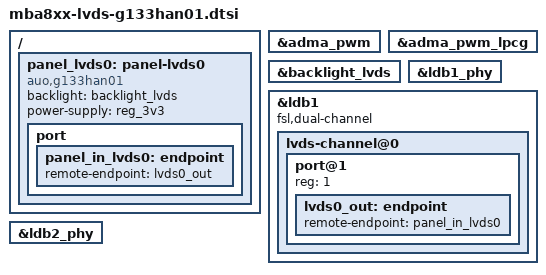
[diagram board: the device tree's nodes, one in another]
// SPDX-License-Identifier: (GPL-2.0-or-later OR MIT)
/*
 * Copyright (c) 2021-2023 TQ-Systems GmbH <linux@ew.tq-group.com>,
 * D-82229 Seefeld, Germany.
 * Author: Alexander Stein
 */

/ {
	panel_lvds0: panel-lvds0 {
		compatible = "auo,g133han01";
		backlight = <&backlight_lvds>;
		power-supply = <&reg_3v3>;

		port {
			panel_in_lvds0: endpoint {
				remote-endpoint = <&lvds0_out>;
			};
		};
	};
};

&adma_pwm {
	status = "okay";
};

&adma_pwm_lpcg {
	status = "okay";
};

&backlight_lvds {
	status = "okay";
};

&ldb1_phy {
	status = "okay";
};

&ldb1 {
	fsl,dual-channel;
	status = "okay";

	lvds-channel@0 {
		status = "okay";

		port@1 {
			reg = <1>;

			lvds0_out: endpoint {
				remote-endpoint = <&panel_in_lvds0>;
			};
		};
	};
};

&ldb2_phy {
	status = "okay";
};
